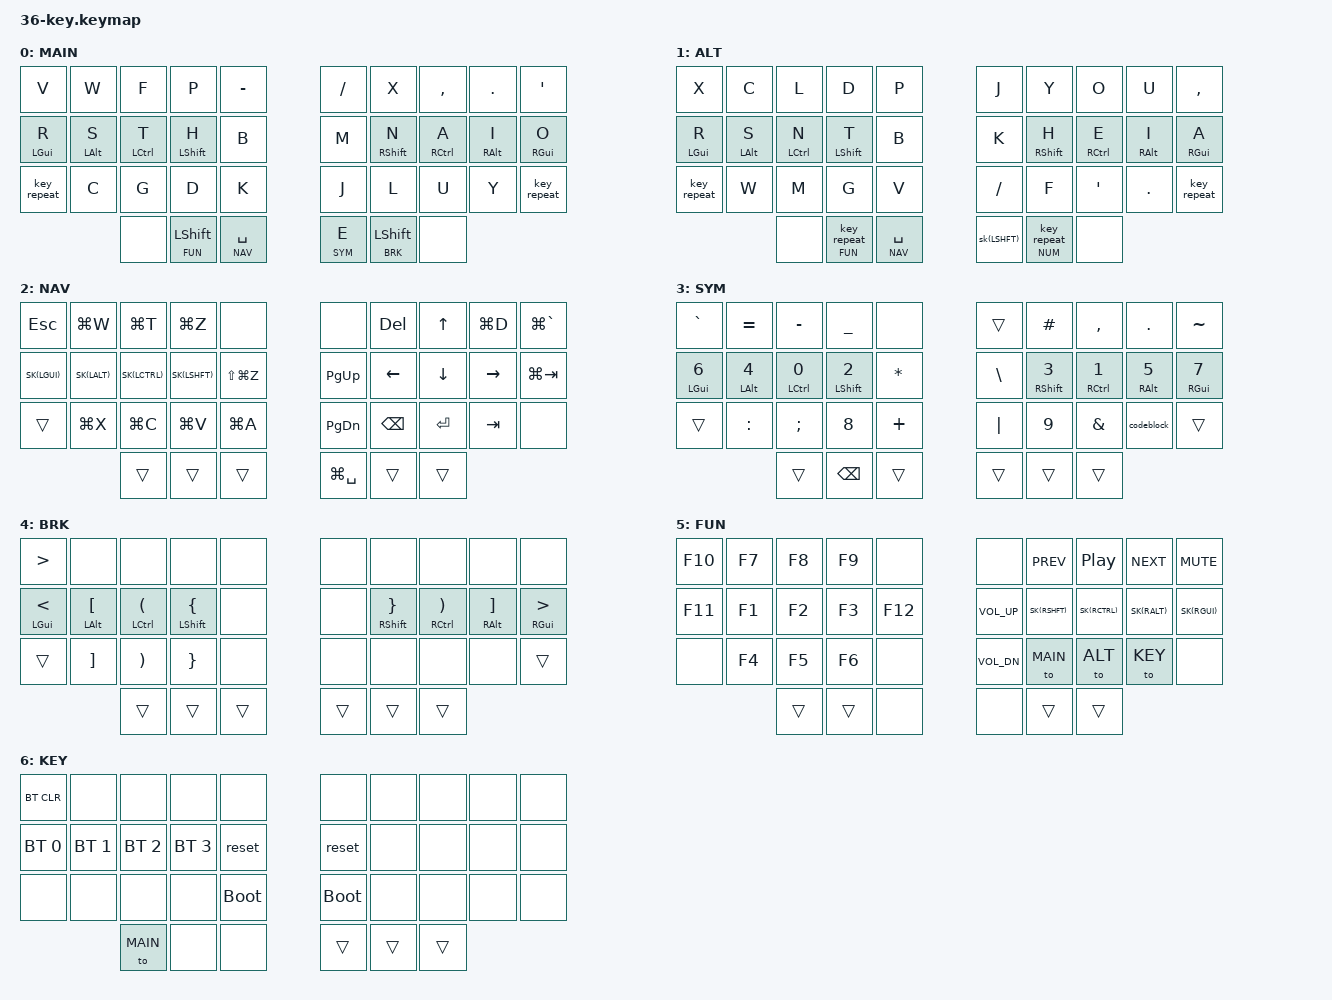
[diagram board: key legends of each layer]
#include <behaviors.dtsi>
#include <dt-bindings/zmk/keys.h>
#include <dt-bindings/zmk/bt.h>
#include <dt-bindings/zmk/outputs.h>

// Layer aliases
#define MAIN  0
#define ALT   1
#define NAV   2
#define SYM   3
#define BRK   4
#define FUN   5
#define KEY   6

// Desktop and tab navigation shortcuts
#define SS_TARGETED &kp LG(LS(N4))
#define SS_FULL     &kp LG(LS(N3))
#define WIN_LEFT    &kp LA(LC(LEFT))
#define WIN_RIGHT   &kp LA(LC(RIGHT))
#define WIN_FULL    &kp LA(LC(RET))
#define SELECT_ALL  &kp LG(A)
#define NEW_TAB     &kp LG(T)
#define FIND        &kp LG(F)
#define COMMAND     &kp LG(K)
#define U_UNDO      &kp LG(Z)
#define U_REDO      &kp LS(LG(Z))
#define U_PST       &kp LG(V)
#define U_CPY       &kp LG(C)
#define U_CUT       &kp LG(X)
#define QUIT        &kp LG(Q)
#define CLOSE       &kp LG(W)
#define APP_SWAP    &kp LG(TAB)
#define WIN_SWAP    &kp LG(GRAVE)
#define ALFRED      &kp LG(SPC)
#define DUPLICATE   &kp LG(D)

#define SK(KEY) &nk KEY KEY

/* Key Position Groups */
#define KEYS_L 0 1 2 3 4 10 11 12 13 14 20 21 22 23 24  // left-hand keys
#define KEYS_R 5 6 7 8 9 15 16 17 18 19 25 26 27 28 29  // right-hand keys
#define THUMBS 30 31 32 33 34 35                        // thumb keys

/* Behavior Settings */
&sl {
  release-after-ms = <250>;
};

&sk {
  release-after-ms = <60000>;
  quick-release;
};

&caps_word {
    continue-list = <BACKSPACE UNDERSCORE MINUS N1 N2 N3 N4 N5 N6 N7 N8 N9 N0>;
};

&lt {
 tapping-term-ms = <175>;
 flavor = "balanced";
};

&mt {
 tapping-term-ms = <175>;
 flavor = "balanced";
};


/ { 
    macros {
        codeblock: codeblock {
            compatible = "zmk,behavior-macro";
            #binding-cells = <0>;
            wait-ms = <0>;
            tap-ms = <0>;
            bindings = <&macro_tap &kp GRAVE &kp GRAVE &kp GRAVE>;
        };

        func: func {
            compatible = "zmk,behavior-macro";
            #binding-cells = <0>;
            wait-ms = <0>;
            tap-ms = <0>;
            bindings = <&macro_tap &kp EQUAL &kp GT>;
        };

        you: you {
            compatible = "zmk,behavior-macro";
            #binding-cells = <0>;
            wait-ms = <0>;
            tap-ms = <0>;
            bindings = <&macro_tap &kp Y &kp O &kp U>;
        };

        mo_nav: mo_nav {
            compatible = "zmk,behavior-macro";
            #binding-cells = <0>;
            wait-ms = <0>;
            tap-ms = <0>;
            bindings
                = <&macro_tap &kp K_CANCEL>
                , <&macro_press &mo NAV>
                , <&macro_pause_for_release>
                , <&macro_release &mo NAV>;
        };

        mo_sym: mo_sym {
            compatible = "zmk,behavior-macro";
            #binding-cells = <0>;
            wait-ms = <0>;
            tap-ms = <0>;
            bindings
                = <&macro_tap &kp K_CANCEL>
                , <&macro_press &mo SYM>
                , <&macro_pause_for_release>
                , <&macro_release &mo SYM>;
        };
    };

    behaviors {
          hml: home-row-left {
            compatible = "zmk,behavior-hold-tap";
            label = "HOME_ROW_LEFT";
            #binding-cells = <2>;
            flavor = "balanced";
            tapping-term-ms = <280>;
            quick-tap-ms = <175>;                // double tapping same key allows for repeating
            global-quick-tap-ms = <60>;         // without PR #1387 use global-quick-tap instead
            bindings = <&kp>, <&kp>;
            hold-trigger-key-positions = <KEYS_R THUMBS>;
            hold-trigger-on-release;             // requires PR #1423
        };

        hmr: home-row-right {
            compatible = "zmk,behavior-hold-tap";
            label = "HOME_ROW_RIGHT";
            #binding-cells = <2>;
            flavor = "balanced";
            tapping-term-ms = <280>;
            quick-tap-ms = <175>;                // double tapping same key allows for repeating
            global-quick-tap-ms = <60>;         // without PR #1387 use global-quick-tap instead
            bindings = <&kp>, <&kp>;
            hold-trigger-key-positions = <KEYS_L THUMBS>;
            hold-trigger-on-release;             // requires PR #1423
        };

        as: alpha_shift {
            compatible = "zmk,behavior-hold-tap";
            label = "ALPHA_SFT";
            #binding-cells = <2>;
            tapping-term-ms = <170>;
            quick-tap-ms = <100>;
            flavor = "tap-preferred";
            bindings = <&kp>, <&kp>;
        };

        // Sticky key on tap, normal key on hold
        // Useful for modifier-clicking without the modifier remaining active
        nk: not_so_sticky_key {
            compatible = "zmk,behavior-hold-tap";
            label = "NOT_SO_STICKY_KEY";
            #binding-cells = <2>;
            tapping_term_ms = <200>;
            flavor = "tap-preferred";
            bindings = <&kp>, <&sk>;
        };

        lst: layer_sticky_tap {
            compatible = "zmk,behavior-hold-tap";
            label = "LAYER_STICKY_TAP";
            #binding-cells = <2>;
            tapping-term-ms = <200>;
            quick_tap_ms = <0>;
            flavor = "tap-preferred";
            bindings = <&mo>, <&sk>;
        };

        lr: layer_repeat {
            compatible = "zmk,behavior-hold-tap";
            label = "LAYER_REPEAT";
            #binding-cells = <2>;
            tapping_term_ms = <200>;
            quick-tap-ms = <175>;
            flavor = "balanced";
            bindings = <&mo>, <&key_repeat>;
        };

        dotexcl: dot_excl {
            compatible = "zmk,behavior-mod-morph";
            label = "DOT_EXCL";
            #binding-cells = <0>;
            bindings = <&kp DOT>, <&kp EXCL>;
            mods = <(MOD_LSFT|MOD_RSFT)>;
        };
    };

    keymap {
        compatible = "zmk,keymap";    
        
// v w f p -     / x , . '
// r s t h b     v n a i o
// ⟳ c g d k     j l u y ⟳

        main_layer {
            label = "MAIN";
            bindings = <
// ╭─────────────┬─────────────┬─────────────┬─────────────┬─────────────╮   ╭─────────────┬─────────────┬─────────────┬─────────────┬─────────────╮
     &kp V         &kp W         &kp F         &kp P         &kp MINUS         &kp SLASH     &kp X         &kp COMMA     &kp DOT       &kp SQT
// ├─────────────┼─────────────┼─────────────┼─────────────┼─────────────┤   ├─────────────┼─────────────┼─────────────┼─────────────┼─────────────┤
     &hml LGUI R   &hml LALT S   &hml LCTRL T  &hml LSHFT H  &kp B             &kp M         &hmr RSHFT N  &hmr RCTRL A  &hmr RALT I   &hmr RGUI O      
// ├─────────────┼─────────────┼─────────────┼─────────────┼─────────────┤   ├─────────────┼─────────────┼─────────────┼─────────────┼─────────────┤
     &key_repeat   &kp C         &kp G         &kp D         &kp K             &kp J         &kp L         &kp U         &kp Y         &key_repeat   
// ╰─────────────┴─────────────┴─────────────┼─────────────┼─────────────┤   ├─────────────┼─────────────┼─────────────┴─────────────┴─────────────╯
                                 &none         &lst FUN LSHFT &lt NAV SPACE    &lt SYM E     &lst BRK LSHFT &none
//                             ╰─────────────┴─────────────┴─────────────╯   ╰─────────────┴─────────────┴─────────────╯
            >;
        };

// w f m p v         , x ' j k
// r s n t b         . a e i h
// x c l d             u o y  

// ['/fun][spc/nav]  [e/sym][oss]

        alt_layer {
            label = "ALT";
            bindings = <
// ╭─────────────┬─────────────┬─────────────┬─────────────┬─────────────╮   ╭─────────────┬─────────────┬─────────────┬─────────────┬─────────────╮
     &kp X         &kp C         &kp L         &kp D         &kp P             &kp J         &kp Y         &kp O         &kp U         &kp COMMA
// ├─────────────┼─────────────┼─────────────┼─────────────┼─────────────┤   ├─────────────┼─────────────┼─────────────┼─────────────┼─────────────┤
     &hml LGUI R   &hml LALT S   &hml LCTRL N  &hml LSHFT T  &kp B             &kp K         &hmr RSHFT H  &hmr RCTRL E  &hmr RALT I   &hmr RGUI A      
// ├─────────────┼─────────────┼─────────────┼─────────────┼─────────────┤   ├─────────────┼─────────────┼─────────────┼─────────────┼─────────────┤
     &key_repeat   &kp W         &kp M         &kp G         &kp V             &kp SLASH     &kp F         &kp SQT       &kp DOT       &key_repeat   
// ╰─────────────┴─────────────┴─────────────┼─────────────┼─────────────┤   ├─────────────┼─────────────┼─────────────┴─────────────┴─────────────╯
                                 &none         &lr FUN 0     &lt NAV SPACE    &sk(LSHFT)    &lr NUM 0     &none
//                             ╰─────────────┴─────────────┴─────────────╯   ╰─────────────┴─────────────┴─────────────╯
            >;
        };

        nav_layer {
            label = "NAV";
            bindings = <
// ╭─────────────┬─────────────┬─────────────┬─────────────┬─────────────╮   ╭─────────────┬─────────────┬─────────────┬─────────────┬─────────────╮
     &kp ESC       CLOSE         NEW_TAB       U_UNDO        &none             &none         &kp DEL       &kp UP        DUPLICATE     WIN_SWAP
// ├─────────────┼─────────────┼─────────────┼─────────────┼─────────────┤   ├─────────────┼─────────────┼─────────────┼─────────────┼─────────────┤
     SK(LGUI)      SK(LALT)      SK(LCTRL)     SK(LSHFT)     U_REDO            &kp PG_UP     &kp LEFT      &kp DOWN      &kp RIGHT     APP_SWAP        
// ├─────────────┼─────────────┼─────────────┼─────────────┼─────────────┤   ├─────────────┼─────────────┼─────────────┼─────────────┼─────────────┤
     &trans        U_CUT         U_CPY         U_PST         SELECT_ALL        &kp PG_DN     &kp BSPC      &kp RET       &kp TAB       &none                             
// ╰─────────────┴─────────────┴─────────────┼─────────────┼─────────────┤   ├─────────────┼─────────────┼─────────────┴─────────────┴─────────────╯
                                 &trans        &trans        &trans            ALFRED        &trans         &trans
//                             ╰─────────────┴─────────────┴─────────────╯   ╰─────────────┴─────────────┴─────────────╯
            >;
        };

        sym_layer { 
            label = "SYM";
            bindings = <
// ╭─────────────┬─────────────┬─────────────┬─────────────┬─────────────╮   ╭─────────────┬─────────────┬─────────────┬─────────────┬─────────────╮
     &kp GRAVE      &kp EQUAL     &kp MINUS    &kp UNDER      &none            &trans        &kp HASH       &kp COMMA     &kp DOT       &kp TILDE
// ├─────────────┼─────────────┼─────────────┼─────────────┼ ────────────┤   ├──────────────┼─────────────┼─────────────┼─────────────┼─────────────┤
     &hml LGUI N6   &hml LALT N4  &hml LCTRL N0 &hml LSHFT N2 &kp STAR         &kp BSLH      &hmr RSHFT N3  &hmr RCTRL N1 &hmr RALT N5  &hmr RGUI N7
// ├─────────────┼─────────────┼─────────────┼─────────────┼─────────────┤   ├─────────────┼─────────────┼─────────────┼─────────────┼─────────────┤
     &trans         &kp COLON     &kp SEMI     &kp N8         &kp PLUS         &kp PIPE      &kp N9         &kp AMPS      &codeblock    &trans            
// ╰─────────────┴─────────────┴─────────────┼─────────────┼─────────────┤   ├─────────────┼─────────────┼─────────────┴─────────────┴─────────────╯
                                 &trans        &kp BSPC       &trans           &trans        &trans         &trans
//                             ╰─────────────┴─────────────┴─────────────╯   ╰─────────────┴─────────────┴─────────────╯
            >;
        };

        bracket_layer {
            label = "BRK";
            bindings = <
// ╭─────────────┬─────────────┬─────────────┬─────────────┬─────────────╮   ╭─────────────┬─────────────┬─────────────┬─────────────┬─────────────╮
     &kp GT        &none          &none        &none         &none             &none         &none          &none        &none         &none
// ├─────────────┼─────────────┼─────────────┼─────────────┼─────────────┤   ├─────────────┼─────────────┼─────────────┼─────────────┼─────────────┤
     &hml LGUI LT  &hml LALT LBKT &hml LCTRL LPAR &as LSHFT LBRC &none         &none         &as RSHFT RBRC &hmr RCTRL RPAR &hmr RALT RBKT &hmr RGUI GT     
// ├─────────────┼─────────────┼─────────────┼─────────────┼─────────────┤   ├─────────────┼─────────────┼─────────────┼─────────────┼─────────────┤
     &trans        &kp RBKT       &kp RPAR    &kp RBRC       &none             &none         &none          &none        &none         &trans
// ╰─────────────┴─────────────┴─────────────┼─────────────┼─────────────┤   ├─────────────┼─────────────┼─────────────┴─────────────┴─────────────╯
                                  &trans      &trans         &trans            &trans        &trans         &trans
//                             ╰─────────────┴─────────────┴─────────────╯   ╰─────────────┴─────────────┴─────────────╯
            >;
        };

        function_layer {
            label = "FUN";
            bindings = <
// ╭─────────────┬─────────────┬─────────────┬─────────────┬─────────────╮   ╭─────────────┬─────────────┬─────────────┬─────────────┬─────────────╮
     &kp F10       &kp F7        &kp F8        &kp F9        &none             &none         &kp C_PREV    &kp C_PP      &kp C_NEXT    &kp C_MUTE
// ├─────────────┼───────────┼─────────────┼───────────────┼─────────────┤   ├─────────────┼─────────────┼─────────────┼─────────────┼─────────────┤
     &kp F11       &kp F1        &kp F2        &kp F3        &kp F12           &kp C_VOL_UP  SK(RSHFT)     SK(RCTRL)     SK(RALT)      SK(RGUI)
// ├─────────────┼───────────┼─────────────┼───────────────┼─────────────┤   ├─────────────┼─────────────┼─────────────┼─────────────┼─────────────┤
     &none         &kp F4        &kp F5        &kp F6        &none             &kp C_VOL_DN  &to MAIN      &to ALT       &to KEY       &none                         
// ├─────────────┼─────────────┼─────────────┴─────────────┴─────────────╯   ├─────────────┼─────────────┼─────────────┴─────────────┴─────────────╯
                                 &trans        &trans        &none             &none         &trans        &trans             
//                             ╰─────────────┴─────────────┴─────────────╯   ╰─────────────┴─────────────┴─────────────╯
            >;
        };
    
        keyboard_layer {
            label = "KEY";
            bindings = <
// ╭─────────────┬─────────────┬─────────────┬─────────────┬─────────────╮   ╭─────────────┬─────────────┬─────────────┬─────────────┬─────────────╮
     &bt BT_CLR    &none         &none         &none         &none              &none         &none        &none         &none         &none
// ├─────────────┼─────────────┼─────────────┼─────────────┼─────────────┤   ├─────────────┼───────────┼─────────────┼───────────────┼─────────────┤
     &bt BT_SEL 0  &bt BT_SEL 1  &bt BT_SEL 2  &bt BT_SEL 3  &reset             &reset        &none        &none         &none         &none
// ├─────────────┼─────────────┼─────────────┼─────────────┼─────────────┤   ├─────────────┼───────────┼─────────────┼───────────────┼─────────────┤
     &none         &none         &none         &none         &bootloader        &bootloader   &none        &none         &none         &none                        
// ├─────────────┼─────────────┼─────────────┴─────────────┴─────────────╯   ├─────────────┼─────────────┼─────────────┴─────────────┴─────────────╯
                                 &to MAIN      &none         &none              &trans        &trans       &trans
//                             ╰─────────────┴─────────────┴─────────────╯   ╰─────────────┴─────────────┴─────────────╯
            >;
        };
    };
};

#include "36-key-combos.dtsi"
